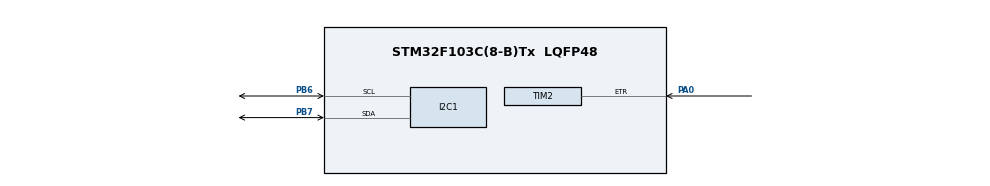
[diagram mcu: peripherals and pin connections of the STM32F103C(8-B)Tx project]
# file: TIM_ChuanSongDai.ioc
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I2C1.I2C_Mode=I2C_Standard
Mcu.Family=STM32F1
Mcu.Name=STM32F103C(8-B)Tx
Mcu.Package=LQFP48
NVIC.PriorityGroup=NVIC_PRIORITYGROUP_4
PA0-WKUP.Signal=S_TIM2_CH1_ETR
PA13.Mode=Serial_Wire
PA13.Signal=SYS_JTMS-SWDIO
PA14.Mode=Serial_Wire
PA14.Signal=SYS_JTCK-SWCLK
PB6.Mode=I2C
PB6.Signal=I2C1_SCL
PB7.Mode=I2C
PB7.Signal=I2C1_SDA
ProjectManager.HeapSize=0x200
ProjectManager.StackSize=0x400
ProjectManager.TargetToolchain=CMake
RCC.APB1Freq_Value=8000000
RCC.APB2Freq_Value=8000000
SH.S_TIM2_CH1_ETR.0=TIM2_ETR,ClockSourceETR_Mode2
TIM2.ClockFilter=15
board=custom

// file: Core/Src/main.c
/* USER CODE BEGIN Header */
/**
  ******************************************************************************
  * @file           : main.c
  * @brief          : Main program body
  ******************************************************************************
  * @attention
  *
  * Copyright (c) 2026 STMicroelectronics.
  * All rights reserved.
  *
  * This software is licensed under terms that can be found in the LICENSE file
  * in the root directory of this software component.
  * If no LICENSE file comes with this software, it is provided AS-IS.
  *
  ******************************************************************************
  */
/* USER CODE END Header */
#include "main.h"
#include "i2c.h"
#include "tim.h"
#include "gpio.h"

/* USER CODE BEGIN Includes */
#include "oled.h"    /* OLED 显示屏驱动 */
#include <stdio.h>   /* 标准输入输出库，用于 sprintf */
/* USER CODE END Includes */

void SystemClock_Config(void);

int main(void)
{

  /* MCU Configuration--------------------------------------------------------*/

  /* Reset of all peripherals, Initializes the Flash interface and the Systick. */
  HAL_Init();

  /* Configure the system clock */
  SystemClock_Config();

  /* Initialize all configured peripherals */
  MX_GPIO_Init();
  MX_I2C1_Init();
  MX_TIM2_Init();
  /* USER CODE BEGIN 2 */
  HAL_Delay(20);        /* 等待 OLED 上电稳定 */
  OLED_Init();          /* 初始化 OLED 显示屏 */
  HAL_TIM_Base_Start(&htim2);  /* 启动 TIM2，通过 ETR（PA0）接收红外传感器脉冲计数 */
  int counter = 0;              /* TIM2 当前计数值 */
  char message[20] = "";        /* OLED 显示缓冲区 */
  /* USER CODE END 2 */

  /* Infinite loop */
  /* USER CODE BEGIN WHILE */
  while (1)
  {
    OLED_NewFrame();                                                  /* 开始新一帧绘制 */

    counter = __HAL_TIM_GET_COUNTER(&htim2);                          /* 读取 TIM2 当前计数值 */
    sprintf(message, "Counter: %d", counter);                         /* 格式化为字符串 */
    OLED_PrintString(0, 0, message, &font16x16, OLED_COLOR_NORMAL);   /* OLED 显示计数值 */

    OLED_ShowFrame();                                                 /* 刷新显示 */
    HAL_Delay(100);                                                   /* 每 100ms 更新一次 */
    /* USER CODE END WHILE */

  }
}

void SystemClock_Config(void)
{
  RCC_OscInitTypeDef RCC_OscInitStruct = {0};
  RCC_ClkInitTypeDef RCC_ClkInitStruct = {0};

  /** Initializes the RCC Oscillators according to the specified parameters
  * in the RCC_OscInitTypeDef structure.
  */
  RCC_OscInitStruct.OscillatorType = RCC_OSCILLATORTYPE_HSI;
  RCC_OscInitStruct.HSIState = RCC_HSI_ON;
  RCC_OscInitStruct.HSICalibrationValue = RCC_HSICALIBRATION_DEFAULT;
  RCC_OscInitStruct.PLL.PLLState = RCC_PLL_NONE;
  if (HAL_RCC_OscConfig(&RCC_OscInitStruct) != HAL_OK)
  {
    Error_Handler();
  }

  /** Initializes the CPU, AHB and APB buses clocks
  */
  RCC_ClkInitStruct.ClockType = RCC_CLOCKTYPE_HCLK|RCC_CLOCKTYPE_SYSCLK
                              |RCC_CLOCKTYPE_PCLK1|RCC_CLOCKTYPE_PCLK2;
  RCC_ClkInitStruct.SYSCLKSource = RCC_SYSCLKSOURCE_HSI;
  RCC_ClkInitStruct.AHBCLKDivider = RCC_SYSCLK_DIV1;
  RCC_ClkInitStruct.APB1CLKDivider = RCC_HCLK_DIV1;
  RCC_ClkInitStruct.APB2CLKDivider = RCC_HCLK_DIV1;

  if (HAL_RCC_ClockConfig(&RCC_ClkInitStruct, FLASH_LATENCY_0) != HAL_OK)
  {
    Error_Handler();
  }
}

void Error_Handler(void)
{
  __disable_irq();
  while (1)
  {
  }
}
